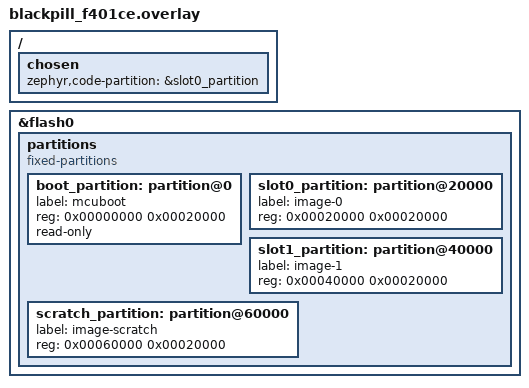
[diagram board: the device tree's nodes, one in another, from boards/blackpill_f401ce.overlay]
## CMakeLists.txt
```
# SPDX-License-Identifier: Apache-2.0

cmake_minimum_required(VERSION 3.13.1)

list(APPEND BOARD_ROOT ${CMAKE_CURRENT_SOURCE_DIR})

find_package(Zephyr REQUIRED HINTS $ENV{ZEPHYR_BASE})
project(blackpill-mcuboot-usb)

target_sources(app PRIVATE src/main.c)
```

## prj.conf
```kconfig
CONFIG_FLASH=y
CONFIG_GPIO=y

CONFIG_LOG=y
CONFIG_LOG_MODE_IMMEDIATE=y
CONFIG_LOG_BACKEND_RTT=y
CONFIG_LOG_BACKEND_RTT_MODE_DROP=y

CONFIG_USE_SEGGER_RTT=y
CONFIG_SEGGER_RTT_BUFFER_SIZE_UP=4096

CONFIG_CONSOLE=y
CONFIG_UART_CONSOLE=n
CONFIG_RTT_CONSOLE=y

CONFIG_MAIN_STACK_SIZE=1024
CONFIG_SYSTEM_WORKQUEUE_STACK_SIZE=512

CONFIG_BOOTLOADER_MCUBOOT=y
CONFIG_IMG_MANAGER=y
```

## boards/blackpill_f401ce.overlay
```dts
/* SPDX-License-Identifier: Apache-2.0 */


/ {
        chosen {
                zephyr,code-partition = &slot0_partition;
        };
};

&flash0 {

	partitions {
		compatible = "fixed-partitions";
		#address-cells = <1>;
		#size-cells = <1>;

		boot_partition: partition@0 {
			label = "mcuboot";
			reg = <0x00000000 0x00020000>;
			read-only;
		};

		slot0_partition: partition@20000 {
			label = "image-0";
			reg = <0x00020000 0x00020000>;
		};

		slot1_partition: partition@40000 {
			label = "image-1";
			reg = <0x00040000 0x00020000>;
		};

		scratch_partition: partition@60000 {
			label = "image-scratch";
			reg = <0x00060000 0x00020000>;
		};
	};
};
```

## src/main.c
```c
/*
 * Copyright (c) 2021 Sergey Matyukevich <geomatsi@gmail.com>
 *
 * SPDX-License-Identifier: Apache-2.0
 */

#include <zephyr.h>

#include <sys/printk.h>

#include <device.h>
#include <devicetree.h>
#include <drivers/gpio.h>

#include <dfu/mcuboot.h>

#define SLEEP_TIME_US 500000

#define LED_NODE DT_NODELABEL(user_led)
#define SW0_NODE DT_ALIAS(sw0)

#define LED	DT_GPIO_LABEL(LED_NODE, gpios)
#define PIN	DT_GPIO_PIN(LED_NODE, gpios)
#define FLAGS	DT_GPIO_FLAGS(LED_NODE, gpios)

#define SW0_GPIO_LABEL	DT_GPIO_LABEL(SW0_NODE, gpios)
#define SW0_GPIO_PIN	DT_GPIO_PIN(SW0_NODE, gpios)
#define SW0_GPIO_FLAGS	(GPIO_INPUT | DT_GPIO_FLAGS(SW0_NODE, gpios))

static struct gpio_callback button_cb_data;

void button_pressed(const struct device *dev, struct gpio_callback *cb,
		    uint32_t pins)
{
	if (boot_is_img_confirmed()) {
		printk("Button pressed at %" PRIu32 "\n", k_cycle_get_32());
		return;
	}

	printk("Confirm new firmware image...\n");

	if (boot_write_img_confirmed()) {
		printk("Failed to confirm new firmware image...\n");
	}
}

void main(void)
{
	const struct device *button;
	const struct device *led;
	uint32_t cycle = 0;
	int ret;

        printk("Hello World!\r\n");

	/* Configure LED */

	led = device_get_binding(LED);
	if (led == NULL) {
		printk("Error: didn't find %s device\n", LED);
		return;
	}

	ret = gpio_pin_configure(led, PIN, GPIO_OUTPUT_ACTIVE | FLAGS);
	if (ret < 0) {
		printk("Error %d: failed to configure %s pin %d\n",
		       ret, LED, PIN);
		return;
	}

	/* Configure user button */

	button = device_get_binding(SW0_GPIO_LABEL);
	if (button == NULL) {
		printk("Error: didn't find %s device\n", SW0_GPIO_LABEL);
		return;
	}

	ret = gpio_pin_configure(button, SW0_GPIO_PIN, SW0_GPIO_FLAGS);
	if (ret != 0) {
		printk("Error %d: failed to configure %s pin %d\n",
		       ret, SW0_GPIO_LABEL, SW0_GPIO_PIN);
		return;
	}

	ret = gpio_pin_interrupt_configure(button, SW0_GPIO_PIN, GPIO_INT_EDGE_TO_ACTIVE);
	if (ret != 0) {
		printk("Error %d: failed to configure interrupt on %s pin %d\n",
			ret, SW0_GPIO_LABEL, SW0_GPIO_PIN);
		return;
	}

	gpio_init_callback(&button_cb_data, button_pressed, BIT(SW0_GPIO_PIN));
	gpio_add_callback(button, &button_cb_data);

	while (1) {
		printk("cycle %u\r\n", cycle++);
		gpio_pin_toggle(led, PIN);
		k_busy_wait(SLEEP_TIME_US);
	}
}
```
